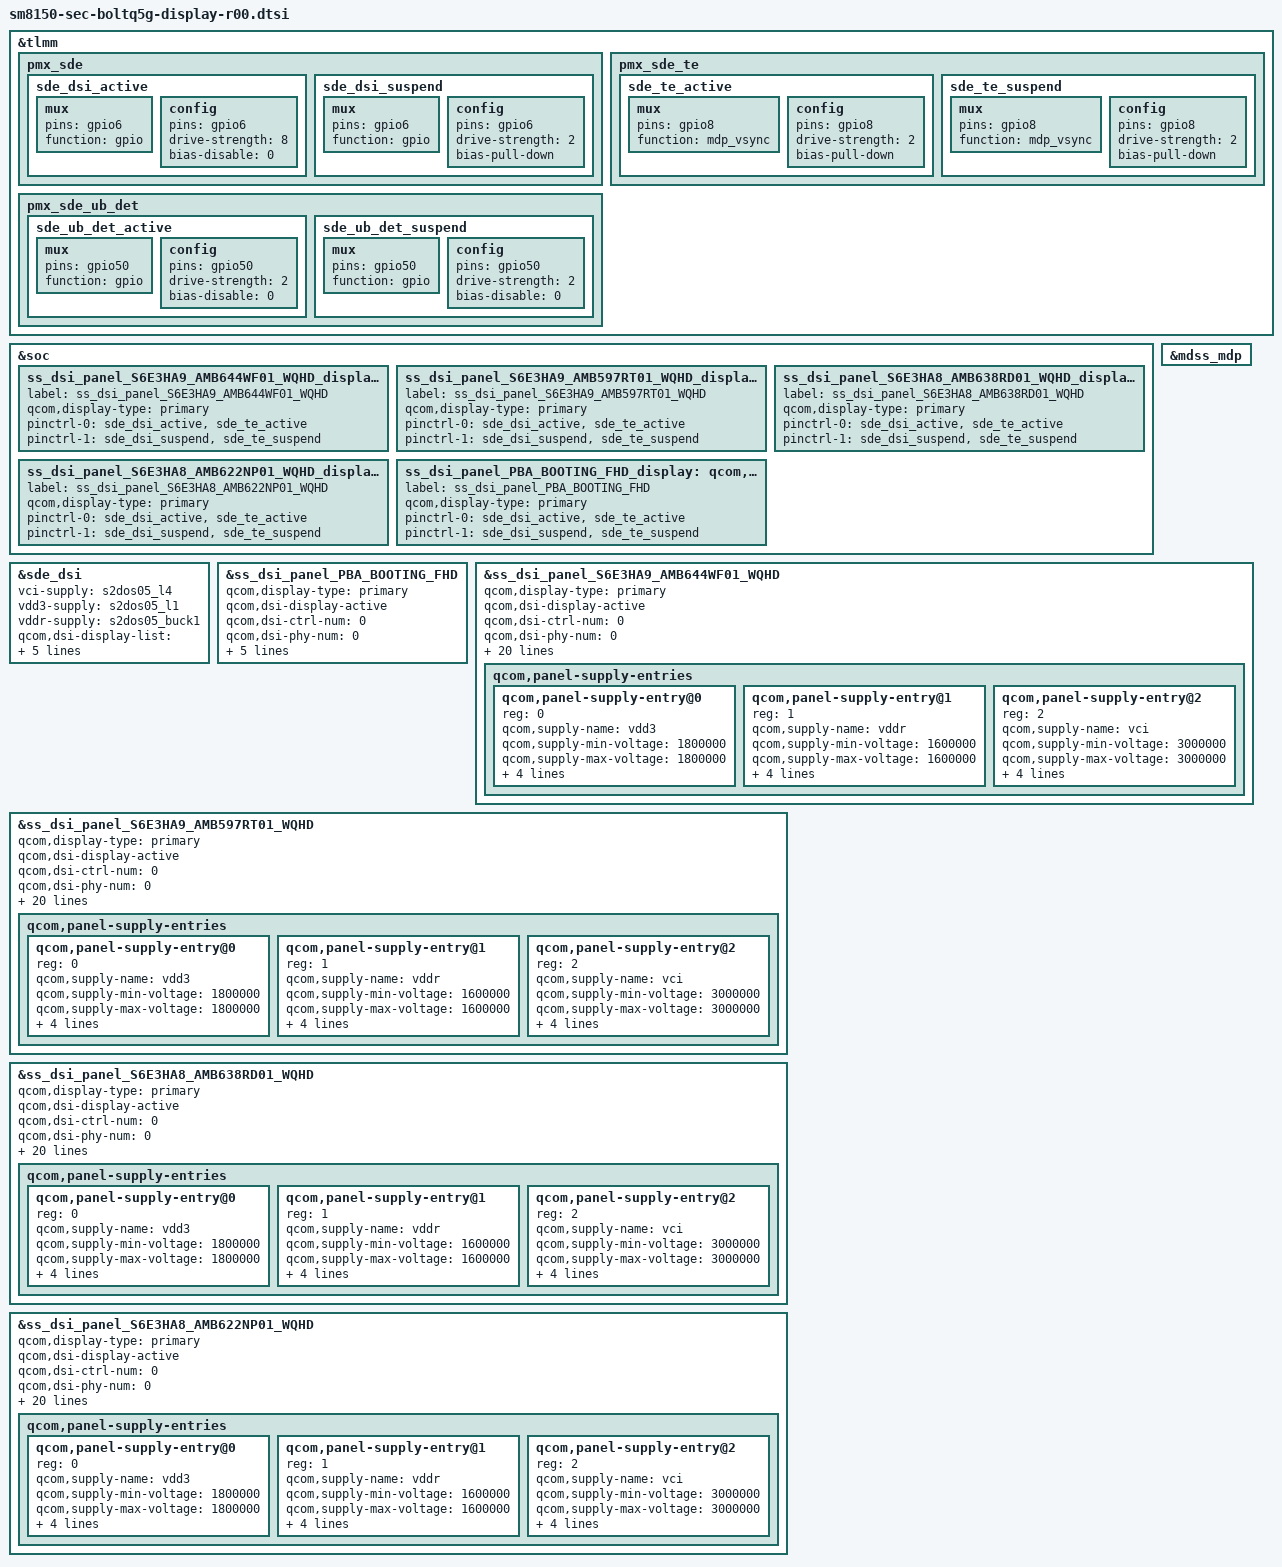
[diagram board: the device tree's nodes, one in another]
/* Copyright (c) 2016-2017, The Linux Foundation. All rights reserved.
 *
 * This program is free software; you can redistribute it and/or modify
 * it under the terms of the GNU General Public License version 2 and
 * only version 2 as published by the Free Software Foundation.
 *
 * This program is distributed in the hope that it will be useful,
 * but WITHOUT ANY WARRANTY; without even the implied warranty of
 * MERCHANTABILITY or FITNESS FOR A PARTICULAR PURPOSE.  See the
 * GNU General Public License for more details.
 */

#include "../../../../../drivers/gpu/drm/msm/samsung/SELF_DISPLAY/self_display_cmd_HA9.dtsi"
#include "../../../../../drivers/gpu/drm/msm/samsung/S6E3HA9_AMB644WF01/dsi_panel_S6E3HA9_AMB644WF01_wqhd_octa_cmd.dtsi"
#include "../../../../../drivers/gpu/drm/msm/samsung/S6E3HA9_AMB597RT01/dsi_panel_S6E3HA9_AMB597RT01_wqhd_octa_cmd.dtsi"
#include "../../../../../drivers/gpu/drm/msm/samsung/SELF_DISPLAY/self_display_cmd_HA8.dtsi"
#include "../../../../../drivers/gpu/drm/msm/samsung/S6E3HA8_AMB638RD01/dsi_panel_S6E3HA8_AMB638RD01_wqhd_octa_cmd_bolt_temp.dtsi"
#include "../../../../../drivers/gpu/drm/msm/samsung/S6E3HA8_AMB622NP01/dsi_panel_S6E3HA8_AMB622NP01_wqhd_octa_cmd.dtsi"
#include "../../../../../drivers/gpu/drm/msm/samsung/PBA_BOOTING/dsi_panel_PBA_BOOTING_fhd_video.dtsi"

#if 0
/{
	aliases {
		spi7 = &qupv3_se7_spi;
	};
};
#endif
&tlmm {
	pmx_sde: pmx_sde {
		sde_dsi_active: sde_dsi_active {
			mux {
				pins = "gpio6";
				function = "gpio";
			};

			config {
				pins = "gpio6";
				drive-strength = <8>;   /* 8 mA */
				bias-disable = <0>;   /* no pull */
			};
		};
		sde_dsi_suspend: sde_dsi_suspend {
			mux {
				pins = "gpio6";
				function = "gpio";
			};

			config {
				pins = "gpio6";
				drive-strength = <2>;   /* 2 mA */
				bias-pull-down;         /* PULL DOWN */
			};
		};
	};
	pmx_sde_te {
		sde_te_active: sde_te_active {
			mux {
				pins = "gpio8";
				function = "mdp_vsync";
			};

			config {
				pins = "gpio8";
				drive-strength = <2>;   /* 2 mA */
				bias-pull-down;         /* PULL DOWN */
			};
		};

		sde_te_suspend: sde_te_suspend {
			mux {
				pins = "gpio8";
				function = "mdp_vsync";
			};

			config {
				pins = "gpio8";
				drive-strength = <2>;   /* 2 mA */
				bias-pull-down;         /* PULL DOWN */
			};
		};
	};
#if 0
	qupv3_se7_spi_pins: qupv3_se7_spi_pins {
		qupv3_se7_spi_active: qupv3_se7_spi_active {
			mux {
				pins = "gpio98", "gpio99", "gpio100",
							"gpio101";
				function = "qup7";
			};

			config {
				pins = "gpio98", "gpio99", "gpio100",
							"gpio101";
				drive-strength = <6>;
				bias-pull-down; /* prevent MISO floating */
			};
		};

		qupv3_se7_spi_sleep: qupv3_se7_spi_sleep {
			mux {
				pins = "gpio98", "gpio99", "gpio100",
							"gpio101";
				function = "gpio";
			};

			config {
				pins = "gpio98", "gpio99", "gpio100",
							"gpio101";
				drive-strength = <6>;
				bias-pull-down;
				input-enable;
			};
		};
	};
#endif
	pmx_sde_ub_det {
		sde_ub_det_active: sde_ub_det_active {
			mux {
				pins = "gpio50";
				function = "gpio";
			};

			config {
				pins = "gpio50";
				drive-strength = <2>;   /* 2 mA */
				bias-disable = <0>;   /* no pull */
			};
		};

		sde_ub_det_suspend: sde_ub_det_suspend {
			mux {
				pins = "gpio50";
				function = "gpio";
			};

			config {
				pins = "gpio50";
				drive-strength = <2>;   /* 2 mA */
				bias-disable = <0>;   /* no pull */
			};
		};
	};
};
#if 0
&soc {
	qupv3_se7_spi: spi@89c000 {
		status = "ok";

		pinctrl-0 = <&qupv3_se7_spi_active>;
		pinctrl-1 = <&qupv3_se7_spi_sleep>;

		ddi_spi:ddi_spi@0  {	// LCD_SPI
			compatible = "ss,ddi-spi";
			reg = <0>;
			spi-max-frequency = <1200000>;
			spi-mode = <0>;
			spi-bpw = <8>;
		};
	};
};
#endif
&soc {
	/* B2 L-Cut 3040 panel */
	ss_dsi_panel_S6E3HA9_AMB644WF01_WQHD_display: qcom,dsi-display@4 {
		label = "ss_dsi_panel_S6E3HA9_AMB644WF01_WQHD";
		qcom,display-type = "primary";

		pinctrl-names = "panel_active", "panel_suspend";
		pinctrl-0 = <&sde_dsi_active &sde_te_active>;
		pinctrl-1 = <&sde_dsi_suspend &sde_te_suspend>;
	};

	/* B1 2960 panel */
	ss_dsi_panel_S6E3HA9_AMB597RT01_WQHD_display: qcom,dsi-display@3 {
		label = "ss_dsi_panel_S6E3HA9_AMB597RT01_WQHD";
		qcom,display-type = "primary";

		pinctrl-names = "panel_active", "panel_suspend";
		pinctrl-0 = <&sde_dsi_active &sde_te_active>;
		pinctrl-1 = <&sde_dsi_suspend &sde_te_suspend>;
	};

	/* crown panel */
	ss_dsi_panel_S6E3HA8_AMB638RD01_WQHD_display: qcom,dsi-display@2 {
		label = "ss_dsi_panel_S6E3HA8_AMB638RD01_WQHD";
		qcom,display-type = "primary";

		pinctrl-names = "panel_active", "panel_suspend";
		pinctrl-0 = <&sde_dsi_active &sde_te_active>;
		pinctrl-1 = <&sde_dsi_suspend &sde_te_suspend>;
	};

	/* star2 panel */
	ss_dsi_panel_S6E3HA8_AMB622NP01_WQHD_display: qcom,dsi-display@1 {
		label = "ss_dsi_panel_S6E3HA8_AMB622NP01_WQHD";
		qcom,display-type = "primary";

		pinctrl-names = "panel_active", "panel_suspend";
		pinctrl-0 = <&sde_dsi_active &sde_te_active>;
		pinctrl-1 = <&sde_dsi_suspend &sde_te_suspend>;
	};

	/* PBA */
	ss_dsi_panel_PBA_BOOTING_FHD_display: qcom,dsi-display@0 {
		label = "ss_dsi_panel_PBA_BOOTING_FHD";
		qcom,display-type = "primary";

		pinctrl-names = "panel_active", "panel_suspend";
		pinctrl-0 = <&sde_dsi_active &sde_te_active>;
		pinctrl-1 = <&sde_dsi_suspend &sde_te_suspend>;
	};
};

/* override display-list / supply for samsung panel */
&sde_dsi {

	vci-supply = <&s2dos05_l4>; /* 3.0V, S2DOS05 LDO4 */
	vdd3-supply = <&s2dos05_l1>; /* 1.8V, S2DOS05 LDO1 */
	vddr-supply = <&s2dos05_buck1>; /* 1.6V, S2DOS05 buck */

	qcom,dsi-display-list =
		<&ss_dsi_panel_S6E3HA9_AMB644WF01_WQHD
		&ss_dsi_panel_S6E3HA9_AMB597RT01_WQHD
		&ss_dsi_panel_S6E3HA8_AMB638RD01_WQHD
		&ss_dsi_panel_S6E3HA8_AMB622NP01_WQHD
		&ss_dsi_panel_PBA_BOOTING_FHD>;
};

&mdss_mdp {
	/* display node, like ss_dsi_panel_S6E3HA8_AMB638RD01_WQHD_display,
	 * will be added by cmdline.
	 * If your board doesn't use cmdline to select display node,
	 * add display node like below.
	 * connectors = <&sde_rscc &sde_wb &sde_dp &ss_dsi_panel_S6E3HA8_AMB638RD01_WQHD_display>;
	 */
};

&ss_dsi_panel_PBA_BOOTING_FHD {
	qcom,display-type = "primary";
	qcom,dsi-display-active;

	qcom,dsi-ctrl-num = <0>;
	qcom,dsi-phy-num = <0>;
	qcom,dsi-select-clocks = "mux_byte_clk0", "mux_pixel_clk0";

	qcom,dsi-panel = <&ss_dsi_panel_PBA_BOOTING_FHD>;

	qcom,platform-reset-gpio = <&tlmm 59 0>;
	qcom,platform-te-gpio = <&tlmm 8 0>;
};

&ss_dsi_panel_S6E3HA9_AMB644WF01_WQHD {
	qcom,display-type = "primary";
	qcom,dsi-display-active;

	qcom,dsi-ctrl-num = <0>;
	qcom,dsi-phy-num = <0>;
	qcom,dsi-select-clocks = "mux_byte_clk0", "mux_pixel_clk0";

	qcom,dsi-panel = <&ss_dsi_panel_S6E3HA9_AMB644WF01_WQHD>;

	qcom,platform-reset-gpio = <&tlmm 59 0>;
	qcom,platform-te-gpio = <&tlmm 8 0>;

	/delete-property/ qcom,panel-mode-gpio;

	qcom,panel-supply-entries {
		#address-cells = <1>;
		#size-cells = <0>;

		qcom,panel-supply-entry@0 {
		    reg = <0>;
		    qcom,supply-name = "vdd3";
		    qcom,supply-min-voltage = <1800000>;
		    qcom,supply-max-voltage = <1800000>;
		    qcom,supply-enable-load = <100000>;
		    qcom,supply-disable-load = <100>;
		    qcom,supply-pre-on-sleep = <0>; /* unit is ms*/
		    qcom,supply-post-on-sleep = <0>;
		};

		qcom,panel-supply-entry@1 {
		    reg = <1>;
		    qcom,supply-name = "vddr";
		    qcom,supply-min-voltage = <1600000>;
		    qcom,supply-max-voltage = <1600000>;
		    qcom,supply-enable-load = <100000>;
		    qcom,supply-disable-load = <100>;
		    qcom,supply-pre-on-sleep = <0>; /* unit is ms*/
		    qcom,supply-post-on-sleep = <0>;
		};

		qcom,panel-supply-entry@2 {
		    reg = <2>;
		    qcom,supply-name = "vci";
		    qcom,supply-min-voltage = <3000000>;
		    qcom,supply-max-voltage = <3000000>;
		    qcom,supply-enable-load = <100000>;
		    qcom,supply-disable-load = <100>;
		    qcom,supply-pre-on-sleep = <0>; /* unit is ms*/
		    qcom,supply-post-on-sleep = <10>;
		};
	};
};

&ss_dsi_panel_S6E3HA9_AMB644WF01_WQHD {
	samsung,esd-irq-gpio1 = <&pm8150_gpios 1 0>; // DISP_DET
	samsung,delayed-display-on = <1>;

	samsung,lpm-power-control;
	samsung,lpm-power-control-supply-name = "vddr";
	samsung,lpm-power-control-supply-min-voltage = <1500000>;
	samsung,lpm-power-control-supply-max-voltage = <1500000>;
	samsung,lpm-power-control-elvss-name = "s2dos05-elvss";
	samsung,lpm-power-control-elvss-lpm-voltage = <2000>;
	samsung,lpm-power-control-elvss-normal-voltage = <8000>;
};

&ss_dsi_panel_S6E3HA9_AMB597RT01_WQHD {
	qcom,display-type = "primary";
	qcom,dsi-display-active;

	qcom,dsi-ctrl-num = <0>;
	qcom,dsi-phy-num = <0>;
	qcom,dsi-select-clocks = "mux_byte_clk0", "mux_pixel_clk0";

	qcom,dsi-panel = <&ss_dsi_panel_S6E3HA9_AMB597RT01_WQHD>;

	qcom,platform-reset-gpio = <&tlmm 59 0>;
	qcom,platform-te-gpio = <&tlmm 8 0>;

	/delete-property/ qcom,panel-mode-gpio;

	qcom,panel-supply-entries {
		#address-cells = <1>;
		#size-cells = <0>;

		qcom,panel-supply-entry@0 {
		    reg = <0>;
		    qcom,supply-name = "vdd3";
		    qcom,supply-min-voltage = <1800000>;
		    qcom,supply-max-voltage = <1800000>;
		    qcom,supply-enable-load = <100000>;
		    qcom,supply-disable-load = <100>;
		    qcom,supply-pre-on-sleep = <0>; /* unit is ms*/
		    qcom,supply-post-on-sleep = <0>;
		};

		qcom,panel-supply-entry@1 {
		    reg = <1>;
		    qcom,supply-name = "vddr";
		    qcom,supply-min-voltage = <1600000>;
		    qcom,supply-max-voltage = <1600000>;
		    qcom,supply-enable-load = <100000>;
		    qcom,supply-disable-load = <100>;
		    qcom,supply-pre-on-sleep = <0>; /* unit is ms*/
		    qcom,supply-post-on-sleep = <0>;
		};

		qcom,panel-supply-entry@2 {
		    reg = <2>;
		    qcom,supply-name = "vci";
		    qcom,supply-min-voltage = <3000000>;
		    qcom,supply-max-voltage = <3000000>;
		    qcom,supply-enable-load = <100000>;
		    qcom,supply-disable-load = <100>;
		    qcom,supply-pre-on-sleep = <0>; /* unit is ms*/
		    qcom,supply-post-on-sleep = <0>;
		};
	};
};

&ss_dsi_panel_S6E3HA9_AMB597RT01_WQHD {
	samsung,esd-irq-gpio1 = <&pm8150_gpios 1 0>; // DISP_DET
	samsung,delayed-display-on = <1>;

	samsung,lpm-power-control;
	samsung,lpm-power-control-supply-name = "vddr";
	samsung,lpm-power-control-supply-min-voltage = <1500000>;
	samsung,lpm-power-control-supply-max-voltage = <1500000>;
	samsung,lpm-power-control-elvss-name = "s2dos05-elvss";
	samsung,lpm-power-control-elvss-lpm-voltage = <2000>;
	samsung,lpm-power-control-elvss-normal-voltage = <8000>;
};

&ss_dsi_panel_S6E3HA8_AMB638RD01_WQHD {
	qcom,display-type = "primary";
	qcom,dsi-display-active;

	qcom,dsi-ctrl-num = <0>;
	qcom,dsi-phy-num = <0>;
	qcom,dsi-select-clocks = "mux_byte_clk0", "mux_pixel_clk0";

	qcom,dsi-panel = <&ss_dsi_panel_S6E3HA8_AMB638RD01_WQHD>;

	qcom,platform-reset-gpio = <&tlmm 59 0>;
	qcom,platform-te-gpio = <&tlmm 8 0>;

	/delete-property/ qcom,panel-mode-gpio;

	qcom,panel-supply-entries {
		#address-cells = <1>;
		#size-cells = <0>;

		qcom,panel-supply-entry@0 {
		    reg = <0>;
		    qcom,supply-name = "vdd3";
		    qcom,supply-min-voltage = <1800000>;
		    qcom,supply-max-voltage = <1800000>;
		    qcom,supply-enable-load = <100000>;
		    qcom,supply-disable-load = <100>;
		    qcom,supply-pre-on-sleep = <0>; /* unit is ms*/
		    qcom,supply-post-on-sleep = <0>;
		};

		qcom,panel-supply-entry@1 {
		    reg = <1>;
		    qcom,supply-name = "vddr";
		    qcom,supply-min-voltage = <1600000>;
		    qcom,supply-max-voltage = <1600000>;
		    qcom,supply-enable-load = <100000>;
		    qcom,supply-disable-load = <100>;
		    qcom,supply-pre-on-sleep = <0>; /* unit is ms*/
		    qcom,supply-post-on-sleep = <0>;
		};

		qcom,panel-supply-entry@2 {
		    reg = <2>;
		    qcom,supply-name = "vci";
		    qcom,supply-min-voltage = <3000000>;
		    qcom,supply-max-voltage = <3000000>;
		    qcom,supply-enable-load = <100000>;
		    qcom,supply-disable-load = <100>;
		    qcom,supply-pre-on-sleep = <0>; /* unit is ms*/
		    qcom,supply-post-on-sleep = <0>;
		};
	};
};

&ss_dsi_panel_S6E3HA8_AMB638RD01_WQHD {
	samsung,esd-irq-gpio1 = <&pm8150_gpios 1 0>; // DISP_DET
	samsung,delayed-display-on = <1>;

	samsung,lpm-power-control;
	samsung,lpm-power-control-supply-name = "vddr";
	samsung,lpm-power-control-supply-min-voltage = <1500000>;
	samsung,lpm-power-control-supply-max-voltage = <1500000>;
	samsung,lpm-power-control-elvss-name = "s2dos05-elvss";
	samsung,lpm-power-control-elvss-lpm-voltage = <2000>;
	samsung,lpm-power-control-elvss-normal-voltage = <8000>;
};

&ss_dsi_panel_S6E3HA8_AMB622NP01_WQHD {
	qcom,display-type = "primary";
	qcom,dsi-display-active;

	qcom,dsi-ctrl-num = <0>;
	qcom,dsi-phy-num = <0>;
	qcom,dsi-select-clocks = "mux_byte_clk0", "mux_pixel_clk0";

	qcom,dsi-panel = <&ss_dsi_panel_S6E3HA8_AMB622NP01_WQHD>;

	qcom,platform-reset-gpio = <&tlmm 59 0>;
	qcom,platform-te-gpio = <&tlmm 8 0>;

	/delete-property/ qcom,panel-mode-gpio;

	qcom,panel-supply-entries {
		#address-cells = <1>;
		#size-cells = <0>;

		qcom,panel-supply-entry@0 {
		    reg = <0>;
		    qcom,supply-name = "vdd3";
		    qcom,supply-min-voltage = <1800000>;
		    qcom,supply-max-voltage = <1800000>;
		    qcom,supply-enable-load = <100000>;
		    qcom,supply-disable-load = <100>;
		    qcom,supply-pre-on-sleep = <0>; /* unit is ms*/
		    qcom,supply-post-on-sleep = <0>;
		};

		qcom,panel-supply-entry@1 {
		    reg = <1>;
		    qcom,supply-name = "vddr";
		    qcom,supply-min-voltage = <1600000>;
		    qcom,supply-max-voltage = <1600000>;
		    qcom,supply-enable-load = <100000>;
		    qcom,supply-disable-load = <100>;
		    qcom,supply-pre-on-sleep = <0>; /* unit is ms*/
		    qcom,supply-post-on-sleep = <0>;
		};

		qcom,panel-supply-entry@2 {
		    reg = <2>;
		    qcom,supply-name = "vci";
		    qcom,supply-min-voltage = <3000000>;
		    qcom,supply-max-voltage = <3000000>;
		    qcom,supply-enable-load = <100000>;
		    qcom,supply-disable-load = <100>;
		    qcom,supply-pre-on-sleep = <0>; /* unit is ms*/
		    qcom,supply-post-on-sleep = <0>;
		};
	};
};

&ss_dsi_panel_S6E3HA8_AMB622NP01_WQHD {
	samsung,esd-irq-gpio1 = <&pm8150_gpios 1 0>; // DISP_DET
	samsung,delayed-display-on = <1>;

	samsung,lpm-power-control;
	samsung,lpm-power-control-supply-name = "vddr";
	samsung,lpm-power-control-supply-min-voltage = <1500000>;
	samsung,lpm-power-control-supply-max-voltage = <1500000>;
	samsung,lpm-power-control-elvss-name = "s2dos05-elvss";
	samsung,lpm-power-control-elvss-lpm-voltage = <2000>;
	samsung,lpm-power-control-elvss-normal-voltage = <8000>;
};

#if 0 // data lane strength..
&mdss_dsi_phy0 {
	qcom,platform-lane-config = [00 20 00 00
					00 20 00 00
					00 20 00 00
					00 20 00 00
					00 20 00 80];
};
#endif
